VERSION ""

NS_ :

BS_:

BU_: BCM Left_Lamp Right_Lamp

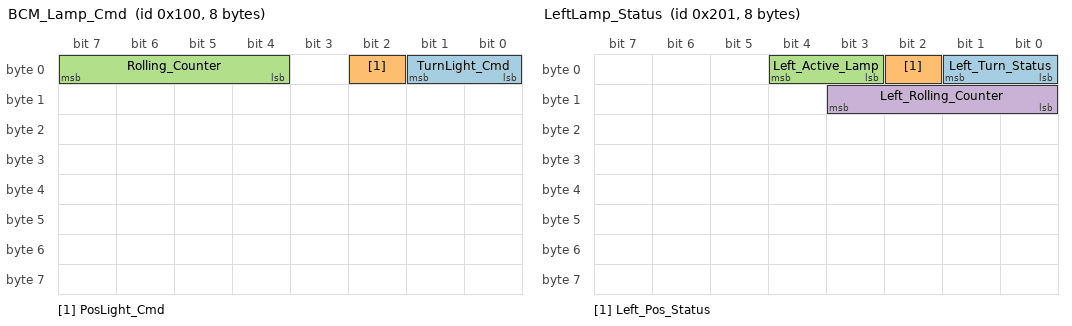
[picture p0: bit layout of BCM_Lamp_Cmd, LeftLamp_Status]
BO_ 256 BCM_Lamp_Cmd: 8 BCM
 SG_ TurnLight_Cmd : 0|2@1+ (1,0) [0|3] "" Left_Lamp,Right_Lamp
 SG_ PosLight_Cmd : 2|1@1+ (1,0) [0|1] "" Left_Lamp,Right_Lamp
 SG_ Rolling_Counter : 4|4@1+ (1,0) [0|15] "" Left_Lamp,Right_Lamp

BO_ 513 LeftLamp_Status: 8 Left_Lamp
 SG_ Left_Turn_Status : 0|2@1+ (1,0) [0|3] "" BCM
 SG_ Left_Pos_Status : 2|1@1+ (1,0) [0|1] "" BCM
 SG_ Left_Active_Lamp : 3|2@1+ (1,0) [0|3] "" BCM
 SG_ Left_Rolling_Counter : 8|4@1+ (1,0) [0|15] "" BCM

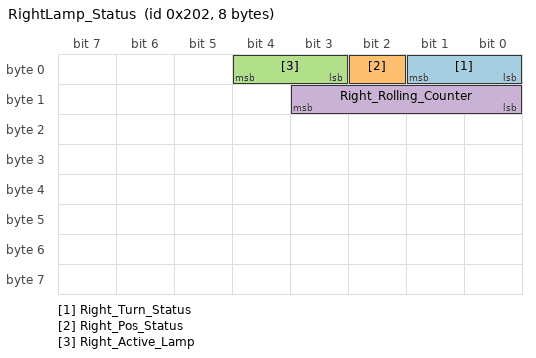
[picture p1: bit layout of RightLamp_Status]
BO_ 514 RightLamp_Status: 8 Right_Lamp
 SG_ Right_Turn_Status : 0|2@1+ (1,0) [0|3] "" BCM
 SG_ Right_Pos_Status : 2|1@1+ (1,0) [0|1] "" BCM
 SG_ Right_Active_Lamp : 3|2@1+ (1,0) [0|3] "" BCM
 SG_ Right_Rolling_Counter : 8|4@1+ (1,0) [0|15] "" BCM

CM_ BO_ 256 "车身控制器 BCM 灯光控制总指令";
CM_ SG_ 256 TurnLight_Cmd "转向灯命令: 0-关, 1-左转向, 2-右转向, 3-双闪警报";
CM_ SG_ 256 PosLight_Cmd "位置灯/示宽灯命令: 0-关, 1-开";
CM_ SG_ 256 Rolling_Counter "0~15 滚动活度计数";

CM_ BO_ 513 "CPS32K214 左车灯节点状态反馈";
CM_ SG_ 513 Left_Turn_Status "左转向灯物理状态: 0-灭, 1-亮, 2-闪烁关, 3-故障";
CM_ SG_ 513 Left_Pos_Status "左位置灯物理状态: 0-灭, 1-常亮";
CM_ SG_ 513 Left_Active_Lamp "当前主导生效灯具(优先级仲裁结果): 0-无, 1-位置灯生效, 2-转向灯优先接管";
CM_ SG_ 513 Left_Rolling_Counter "左灯反馈滚动计数";

CM_ BO_ 514 "云途 YTM32 右车灯节点状态反馈";
CM_ SG_ 514 Right_Turn_Status "右转向灯物理状态: 0-灭, 1-亮, 2-闪烁关, 3-故障";
CM_ SG_ 514 Right_Pos_Status "右位置灯物理状态: 0-灭, 1-常亮";
CM_ SG_ 514 Right_Active_Lamp "当前主导生效灯具(优先级仲裁结果): 0-无, 1-位置灯生效, 2-转向灯优先接管";
CM_ SG_ 514 Right_Rolling_Counter "右灯反馈滚动计数";

VAL_ 256 TurnLight_Cmd 0 "OFF" 1 "Left_Turn" 2 "Right_Turn" 3 "Hazard_Flashing" ;
VAL_ 256 PosLight_Cmd 0 "OFF" 1 "ON" ;
VAL_ 513 Left_Turn_Status 0 "OFF" 1 "BLINK_ON" 2 "BLINK_OFF" 3 "FAULT" ;
VAL_ 513 Left_Pos_Status 0 "OFF" 1 "ON" ;
VAL_ 513 Left_Active_Lamp 0 "NONE" 1 "POS_LIGHT" 2 "TURN_LIGHT" 3 "BOTH" ;
VAL_ 514 Right_Turn_Status 0 "OFF" 1 "BLINK_ON" 2 "BLINK_OFF" 3 "FAULT" ;
VAL_ 514 Right_Pos_Status 0 "OFF" 1 "ON" ;
VAL_ 514 Right_Active_Lamp 0 "NONE" 1 "POS_LIGHT" 2 "TURN_LIGHT" 3 "BOTH" ;
